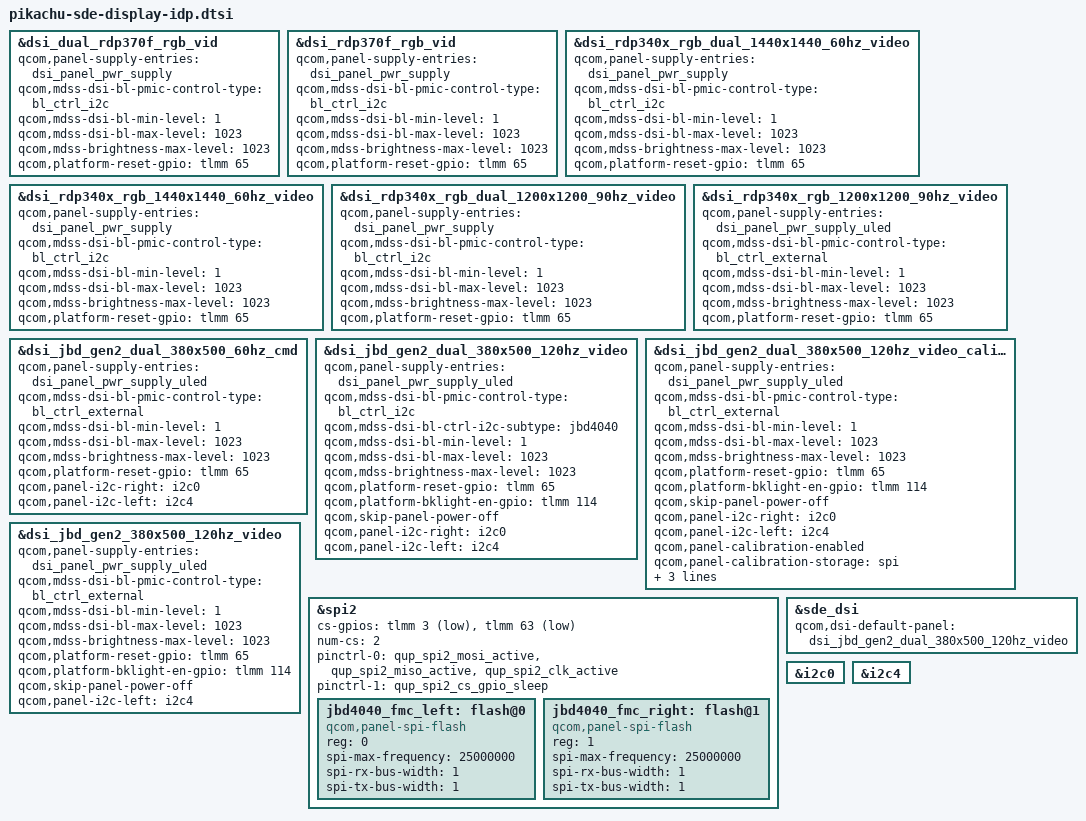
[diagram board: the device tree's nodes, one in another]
// SPDX-License-Identifier: BSD-3-Clause
/*
 * Copyright (c) Qualcomm Technologies, Inc. and/or its subsidiaries.
 */

#include <dt-bindings/gpio/gpio.h>
#include "pikachu-sde-display.dtsi"

&dsi_dual_rdp370f_rgb_vid {
	qcom,panel-supply-entries = <&dsi_panel_pwr_supply>;
	qcom,mdss-dsi-bl-pmic-control-type = "bl_ctrl_i2c";
	qcom,mdss-dsi-bl-min-level = <1>;
	qcom,mdss-dsi-bl-max-level = <1023>;
	qcom,mdss-brightness-max-level = <1023>;
	qcom,platform-reset-gpio = <&tlmm 65 0>;
};

&dsi_rdp370f_rgb_vid {
	qcom,panel-supply-entries = <&dsi_panel_pwr_supply>;
	qcom,mdss-dsi-bl-pmic-control-type = "bl_ctrl_i2c";
	qcom,mdss-dsi-bl-min-level = <1>;
	qcom,mdss-dsi-bl-max-level = <1023>;
	qcom,mdss-brightness-max-level = <1023>;
	qcom,platform-reset-gpio = <&tlmm 65 0>;
};

&dsi_rdp340x_rgb_dual_1440x1440_60hz_video {
	qcom,panel-supply-entries = <&dsi_panel_pwr_supply>;
	qcom,mdss-dsi-bl-pmic-control-type = "bl_ctrl_i2c";
	qcom,mdss-dsi-bl-min-level = <1>;
	qcom,mdss-dsi-bl-max-level = <1023>;
	qcom,mdss-brightness-max-level = <1023>;
	qcom,platform-reset-gpio = <&tlmm 65 0>;
};

&dsi_rdp340x_rgb_1440x1440_60hz_video {
	qcom,panel-supply-entries = <&dsi_panel_pwr_supply>;
	qcom,mdss-dsi-bl-pmic-control-type = "bl_ctrl_i2c";
	qcom,mdss-dsi-bl-min-level = <1>;
	qcom,mdss-dsi-bl-max-level = <1023>;
	qcom,mdss-brightness-max-level = <1023>;
	qcom,platform-reset-gpio = <&tlmm 65 0>;
};

&dsi_rdp340x_rgb_dual_1200x1200_90hz_video {
	qcom,panel-supply-entries = <&dsi_panel_pwr_supply>;
	qcom,mdss-dsi-bl-pmic-control-type = "bl_ctrl_i2c";
	qcom,mdss-dsi-bl-min-level = <1>;
	qcom,mdss-dsi-bl-max-level = <1023>;
	qcom,mdss-brightness-max-level = <1023>;
	qcom,platform-reset-gpio = <&tlmm 65 0>;
};

&dsi_rdp340x_rgb_1200x1200_90hz_video {
	qcom,panel-supply-entries = <&dsi_panel_pwr_supply_uled>;
	qcom,mdss-dsi-bl-pmic-control-type = "bl_ctrl_external";
	qcom,mdss-dsi-bl-min-level = <1>;
	qcom,mdss-dsi-bl-max-level = <1023>;
	qcom,mdss-brightness-max-level = <1023>;
	qcom,platform-reset-gpio = <&tlmm 65 0>;
};

&dsi_jbd_gen2_dual_380x500_60hz_cmd {
	qcom,panel-supply-entries = <&dsi_panel_pwr_supply_uled>;
	qcom,mdss-dsi-bl-pmic-control-type = "bl_ctrl_external";
	qcom,mdss-dsi-bl-min-level = <1>;
	qcom,mdss-dsi-bl-max-level = <1023>;
	qcom,mdss-brightness-max-level = <1023>;
	qcom,platform-reset-gpio = <&tlmm 65 0>;
	qcom,panel-i2c-right = <&i2c0>;
	qcom,panel-i2c-left = <&i2c4>;
};

&dsi_jbd_gen2_dual_380x500_120hz_video {
	qcom,panel-supply-entries = <&dsi_panel_pwr_supply_uled>;
	qcom,mdss-dsi-bl-pmic-control-type = "bl_ctrl_i2c";
	qcom,mdss-dsi-bl-ctrl-i2c-subtype = "jbd4040";
	qcom,mdss-dsi-bl-min-level = <1>;
	qcom,mdss-dsi-bl-max-level = <1023>;
	qcom,mdss-brightness-max-level = <1023>;
	qcom,platform-reset-gpio = <&tlmm 65 0>;
	qcom,platform-bklight-en-gpio = <&tlmm 114 0>;
	qcom,skip-panel-power-off;
	qcom,panel-i2c-right = <&i2c0>;
	qcom,panel-i2c-left = <&i2c4>;
};

&dsi_jbd_gen2_dual_380x500_120hz_video_calibrated {
	qcom,panel-supply-entries = <&dsi_panel_pwr_supply_uled>;
	qcom,mdss-dsi-bl-pmic-control-type = "bl_ctrl_external";
	qcom,mdss-dsi-bl-min-level = <1>;
	qcom,mdss-dsi-bl-max-level = <1023>;
	qcom,mdss-brightness-max-level = <1023>;
	qcom,platform-reset-gpio = <&tlmm 65 0>;
	qcom,platform-bklight-en-gpio = <&tlmm 114 0>;
	qcom,skip-panel-power-off;
	qcom,panel-i2c-right = <&i2c0>;
	qcom,panel-i2c-left = <&i2c4>;
	qcom,panel-calibration-enabled;
	qcom,panel-calibration-storage = "spi";
	qcom,panel-calibration-left = <&jbd4040_fmc_left>;
	qcom,panel-calibration-right = <&jbd4040_fmc_right>;
};

&dsi_jbd_gen2_380x500_120hz_video {
	qcom,panel-supply-entries = <&dsi_panel_pwr_supply_uled>;
	qcom,mdss-dsi-bl-pmic-control-type = "bl_ctrl_external";
	qcom,mdss-dsi-bl-min-level = <1>;
	qcom,mdss-dsi-bl-max-level = <1023>;
	qcom,mdss-brightness-max-level = <1023>;
	qcom,platform-reset-gpio = <&tlmm 65 0>;
	qcom,platform-bklight-en-gpio = <&tlmm 114 0>;
	qcom,skip-panel-power-off;
	qcom,panel-i2c-left = <&i2c4>;
};

&spi2 {
	cs-gpios = <&tlmm 3 GPIO_ACTIVE_LOW>,
		   <&tlmm 63 GPIO_ACTIVE_LOW>;
	num-cs = <2>;

	pinctrl-names = "default",
			"sleep";
	pinctrl-0 = <&qup_spi2_mosi_active>, <&qup_spi2_miso_active>,
		    <&qup_spi2_clk_active>;
	pinctrl-1 = <&qup_spi2_cs_gpio_sleep>;

	status = "ok";

	/*
	 * JBD4040 calibration flash devices.
	 * To read flash device using mtd drivers use:
	 * compatible = "jedec,spi-nor".
	 */
	jbd4040_fmc_left: flash@0 {
		compatible = "qcom,panel-spi-flash";
		reg = <0>;
		spi-max-frequency = <25000000>;

		spi-rx-bus-width = <1>;
		spi-tx-bus-width = <1>;
	};

	jbd4040_fmc_right: flash@1 {
		compatible = "qcom,panel-spi-flash";
		reg = <1>;
		spi-max-frequency = <25000000>;

		spi-rx-bus-width = <1>;
		spi-tx-bus-width = <1>;
	};
};

&sde_dsi {
	qcom,dsi-default-panel = <&dsi_jbd_gen2_dual_380x500_120hz_video>;
};

&i2c0 {
	status = "ok";
};

&i2c4 {
	status = "ok";
};
